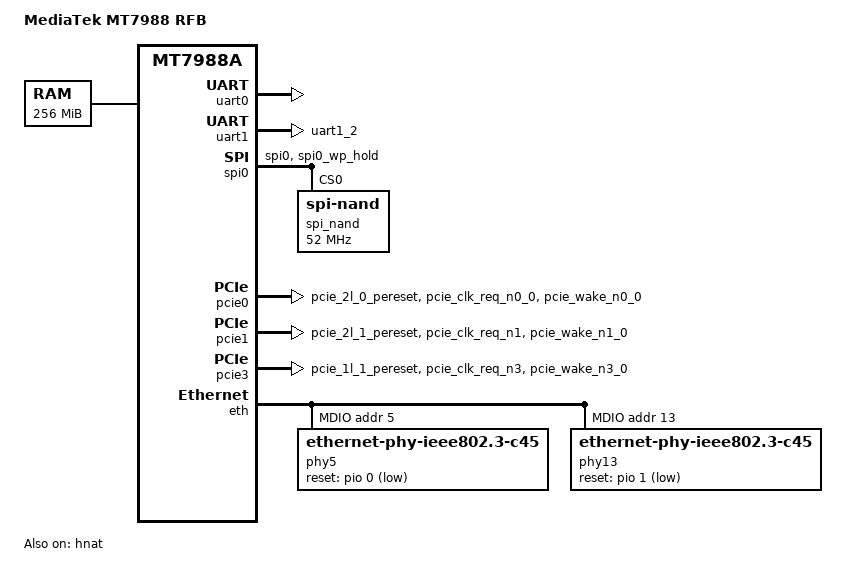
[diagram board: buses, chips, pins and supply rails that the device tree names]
/dts-v1/;
#include "mt7988.dtsi"
/ {
	model = "MediaTek MT7988 RFB";
	compatible = "mediatek,mt7988a-spim-nand";
	chosen {
		bootargs = "console=ttyS0,115200n1 loglevel=8  \
				earlycon=uart8250,mmio32,0x11000000 failsafe=true";
	};

	memory {
		reg = <0 0x40000000 0 0x10000000>;
	};

	nmbm_spim_nand {
		compatible = "generic,nmbm";

		#address-cells = <1>;
		#size-cells = <1>;

		lower-mtd-device = <&spi_nand>;
		forced-create;

		partitions {
			compatible = "fixed-partitions";
			#address-cells = <1>;
			#size-cells = <1>;

			partition@0 {
				label = "BL2";
				reg = <0x00000 0x0100000>;
				read-only;
			};

			partition@100000 {
				label = "u-boot-env";
				reg = <0x0100000 0x0080000>;
			};

			partition@180000 {
				label = "Factory";
				reg = <0x180000 0x0400000>;
			};

			partition@580000 {
				label = "FIP";
				reg = <0x580000 0x0200000>;
			};

			partition@780000 {
				label = "ubi";
				reg = <0x780000 0x4000000>;
			};
		};
	};

	wsys_adie: wsys_adie@0 {
	// fpga cases need to manual change adie_id / sku_type for dvt only
		compatible = "mediatek,rebb-mt7988-adie";
		adie_id = <7976>;
		sku_type = <3000>;
	};
};

&uart0 {
	status = "okay";
};

&uart1 {
	pinctrl-names = "default";
	pinctrl-0 = <&uart1_pins>;
	status = "okay";
};

&spi0 {
	pinctrl-names = "default";
	pinctrl-0 = <&spi0_flash_pins>;
	status = "okay";
	spi_nand: spi_nand@0 {
		#address-cells = <1>;
		#size-cells = <1>;
		compatible = "spi-nand";
		spi-cal-enable;
		spi-cal-mode = "read-data";
		spi-cal-datalen = <7>;
		spi-cal-data = /bits/ 8 <0x53 0x50 0x49 0x4E 0x41 0x4E 0x44>;
		spi-cal-addrlen = <5>;
		spi-cal-addr = /bits/ 32 <0x0 0x0 0x0 0x0 0x0>;
		reg = <0>;
		spi-max-frequency = <52000000>;
		spi-tx-buswidth = <4>;
		spi-rx-buswidth = <4>;
	};
};

&spi1 {
	pinctrl-names = "default";
	/* pin shared with snfi */
	pinctrl-0 = <&spic_pins>;
	status = "disabled";
};

&pcie0 {
	pinctrl-names = "default";
	pinctrl-0 = <&pcie0_pins>;
	status = "okay";
};

&pcie1 {
	pinctrl-names = "default";
	pinctrl-0 = <&pcie1_pins>;
	status = "okay";
};

&pcie2 {
	pinctrl-names = "default";
	pinctrl-0 = <&pcie2_pins>;
	status = "disabled";
};

&pcie3 {
	pinctrl-names = "default";
	pinctrl-0 = <&pcie3_pins>;
	status = "okay";
};

&pio {
	pcie0_pins: pcie0-pins {
		mux {
			function = "pcie";
			groups = "pcie_2l_0_pereset", "pcie_clk_req_n0_0",
				 "pcie_wake_n0_0";
		};
	};

	pcie1_pins: pcie1-pins {
		mux {
			function = "pcie";
			groups = "pcie_2l_1_pereset", "pcie_clk_req_n1",
				 "pcie_wake_n1_0";
		};
	};

	pcie2_pins: pcie2-pins {
		mux {
			function = "pcie";
			groups = "pcie_1l_0_pereset", "pcie_clk_req_n2_0",
				 "pcie_wake_n2_0";
		};
	};

	pcie3_pins: pcie3-pins {
		mux {
			function = "pcie";
			groups = "pcie_1l_1_pereset", "pcie_clk_req_n3",
				 "pcie_wake_n3_0";
		};
	};

	spi0_flash_pins: spi0-pins {
		mux {
			function = "spi";
			groups = "spi0", "spi0_wp_hold";
		};
	};

	spic_pins: spi1-pins {
		mux {
			function = "spi";
			groups = "spi1_1";
		};
	};

	uart1_pins: uart1-pins-80-to-83 {
		mux {
			function = "uart";
			groups = "uart1_2";
		};
	};
};

&watchdog {
	status = "disabled";
};

&eth {
	status = "okay";

	gmac0: mac@0 {
		compatible = "mediatek,eth-mac";
		reg = <0>;
		phy-mode = "10gbase-kr";

		fixed-link {
			speed = <2500>;
			full-duplex;
			pause;
		};
	};

	gmac1: mac@1 {
		compatible = "mediatek,eth-mac";
		reg = <1>;
		phy-mode = "2500base-x";
		phy-handle = <&phy13>;
	};

	gmac2: mac@2 {
		compatible = "mediatek,eth-mac";
		reg = <2>;
		phy-mode = "2500base-x";
		phy-handle = <&phy5>;
	};

	mdio: mdio-bus {
		#address-cells = <1>;
		#size-cells = <0>;

		phy5: phy@5 {
			compatible = "ethernet-phy-ieee802.3-c45";
			reg = <5>;
			reset-gpios = <&pio 0 1>;
			reset-assert-us = <600>;
			reset-deassert-us = <20000>;
		};

		phy13: phy@13 {
			compatible = "ethernet-phy-ieee802.3-c45";
			reg = <13>;
			reset-gpios = <&pio 1 1>;
			reset-assert-us = <600>;
			reset-deassert-us = <20000>;
		};
	};
};

&hnat {
	mtketh-wan = "eth1";
	mtketh-lan = "eth0";
	mtketh-lan2 = "eth2";
	mtketh-max-gmac = <3>;
	status = "okay";
};
